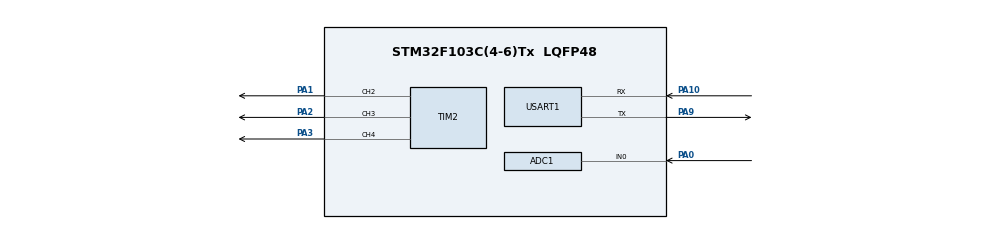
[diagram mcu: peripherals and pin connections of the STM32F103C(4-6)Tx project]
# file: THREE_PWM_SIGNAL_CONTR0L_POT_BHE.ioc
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ADC1.Channel-0\#ChannelRegularConversion=ADC_CHANNEL_0
ADC1.NbrOfConversionFlag=1
ADC1.Rank-0\#ChannelRegularConversion=1
ADC1.SamplingTime-0\#ChannelRegularConversion=ADC_SAMPLETIME_1CYCLE_5
ADC1.master=1
Mcu.Family=STM32F1
Mcu.Name=STM32F103C(4-6)Tx
Mcu.Package=LQFP48
NVIC.PriorityGroup=NVIC_PRIORITYGROUP_4
PA0-WKUP.Signal=ADCx_IN0
PA1.Signal=S_TIM2_CH2
PA10.Mode=Asynchronous
PA10.Signal=USART1_RX
PA2.Signal=S_TIM2_CH3
PA3.Signal=S_TIM2_CH4
PA9.Mode=Asynchronous
PA9.Signal=USART1_TX
PD0-OSC_IN.Mode=HSE-External-Oscillator
PD0-OSC_IN.Signal=RCC_OSC_IN
PD1-OSC_OUT.Mode=HSE-External-Oscillator
PD1-OSC_OUT.Signal=RCC_OSC_OUT
ProjectManager.HeapSize=0x200
ProjectManager.StackSize=0x400
ProjectManager.TargetToolchain=STM32CubeIDE
RCC.APB1Freq_Value=8000000
RCC.APB2Freq_Value=8000000
SH.ADCx_IN0.0=ADC1_IN0,IN0
SH.S_TIM2_CH2.0=TIM2_CH2,PWM Generation2 CH2
SH.S_TIM2_CH3.0=TIM2_CH3,PWM Generation3 CH3
SH.S_TIM2_CH4.0=TIM2_CH4,PWM Generation4 CH4
TIM2.Channel-PWM\ Generation2\ CH2=TIM_CHANNEL_2
TIM2.Channel-PWM\ Generation3\ CH3=TIM_CHANNEL_3
TIM2.Channel-PWM\ Generation4\ CH4=TIM_CHANNEL_4
USART1.VirtualMode=VM_ASYNC
VP_TIM2_VS_ClockSourceINT.Mode=Internal
board=custom

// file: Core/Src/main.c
/* USER CODE BEGIN Header */
/**
  ******************************************************************************
  * @file           : main.c
  * @brief          : Main program body
  ******************************************************************************
  * @attention
  *
  * Copyright (c) 2023 STMicroelectronics.
  * All rights reserved.
  *
  * This software is licensed under terms that can be found in the LICENSE file
  * in the root directory of this software component.
  * If no LICENSE file comes with this software, it is provided AS-IS.
  *
  ******************************************************************************
  */
/* USER CODE END Header */
#include "main.h"

ADC_HandleTypeDef hadc1;

TIM_HandleTypeDef htim2;

UART_HandleTypeDef huart1;

void SystemClock_Config(void);
static void MX_GPIO_Init(void);
static void MX_ADC1_Init(void);
static void MX_TIM2_Init(void);
static void MX_USART1_UART_Init(void);

int main(void)
{

	uint16_t test;
	char msg[10];

  /* MCU Configuration--------------------------------------------------------*/

  /* Reset of all peripherals, Initializes the Flash interface and the Systick. */
  HAL_Init();

  /* Configure the system clock */
  SystemClock_Config();

  /* Initialize all configured peripherals */
  MX_GPIO_Init();
  MX_ADC1_Init();
  MX_TIM2_Init();
  MX_USART1_UART_Init();
  /* USER CODE BEGIN 2 */

  /* Start PWM for 2 */
    if (HAL_TIM_PWM_Start(&htim2, TIM_CHANNEL_2) != HAL_OK)
    {
      /* PWM Generation Error */
      Error_Handler();
    }

    if (HAL_TIM_PWM_Start(&htim2, TIM_CHANNEL_3) != HAL_OK)
    {
      /* PWM Generation Error */
      Error_Handler();
    }

    if (HAL_TIM_PWM_Start(&htim2, TIM_CHANNEL_4) != HAL_OK)
    {
      /* PWM Generation Error */
      Error_Handler();
    }

  /* USER CODE END 2 */

  /* Infinite loop */
  while (1)
  {

	 HAL_ADC_Start(&hadc1);
	 HAL_ADC_PollForConversion(&hadc1,10000);
	 test=HAL_ADC_GetValue(&hadc1);

	 uint16_t potValue = HAL_ADC_GetValue(&hadc1);
	 uint32_t dutyCycle = (uint32_t)((float)potValue / 4095.0 * 35999.0); // Assuming 12-bit ADC

	 test = test*0.001220703125; // conversion adc value into voltage
	 sprintf(msg,"%hu\r\n",test);
     HAL_UART_Transmit(&huart1,(uint8_t *)msg,strlen(msg),100000);
     HAL_Delay(500);

     __HAL_TIM_SET_COMPARE(&htim2, TIM_CHANNEL_2, dutyCycle);

     __HAL_TIM_SET_COMPARE(&htim2, TIM_CHANNEL_3, dutyCycle);

     __HAL_TIM_SET_COMPARE(&htim2, TIM_CHANNEL_3, dutyCycle);

	 HAL_TIM_PWM_Start(&htim2, TIM_CHANNEL_2);

	 		      // Delay for a while
	 	HAL_Delay(500);

	 		      // Turn off the LED on PA1
	 	HAL_TIM_PWM_Stop(&htim2, TIM_CHANNEL_2);

	 		      // Turn on the LED on PA2 (Channel 2)
	 	HAL_TIM_PWM_Start(&htim2, TIM_CHANNEL_3);

	 		      // Delay for a while
	 	HAL_Delay(500);

	 		      // Turn off the LED on PA2
	 	HAL_TIM_PWM_Stop(&htim2, TIM_CHANNEL_3);

	 		      // Turn on the LED on PA3 (Channel 3)
	 	HAL_TIM_PWM_Start(&htim2, TIM_CHANNEL_4);

	 		      // Delay for a while
	 	HAL_Delay(500);

	 		      // Turn off the LED on PA3
	 	HAL_TIM_PWM_Stop(&htim2, TIM_CHANNEL_4);
  }
}

void SystemClock_Config(void)
{
  RCC_OscInitTypeDef RCC_OscInitStruct = {0};
  RCC_ClkInitTypeDef RCC_ClkInitStruct = {0};
  RCC_PeriphCLKInitTypeDef PeriphClkInit = {0};

  /** Initializes the RCC Oscillators according to the specified parameters
  * in the RCC_OscInitTypeDef structure.
  */
  RCC_OscInitStruct.OscillatorType = RCC_OSCILLATORTYPE_HSI;
  RCC_OscInitStruct.HSIState = RCC_HSI_ON;
  RCC_OscInitStruct.HSICalibrationValue = RCC_HSICALIBRATION_DEFAULT;
  RCC_OscInitStruct.PLL.PLLState = RCC_PLL_NONE;
  if (HAL_RCC_OscConfig(&RCC_OscInitStruct) != HAL_OK)
  {
    Error_Handler();
  }

  /** Initializes the CPU, AHB and APB buses clocks
  */
  RCC_ClkInitStruct.ClockType = RCC_CLOCKTYPE_HCLK|RCC_CLOCKTYPE_SYSCLK
                              |RCC_CLOCKTYPE_PCLK1|RCC_CLOCKTYPE_PCLK2;
  RCC_ClkInitStruct.SYSCLKSource = RCC_SYSCLKSOURCE_HSI;
  RCC_ClkInitStruct.AHBCLKDivider = RCC_SYSCLK_DIV1;
  RCC_ClkInitStruct.APB1CLKDivider = RCC_HCLK_DIV1;
  RCC_ClkInitStruct.APB2CLKDivider = RCC_HCLK_DIV1;

  if (HAL_RCC_ClockConfig(&RCC_ClkInitStruct, FLASH_LATENCY_0) != HAL_OK)
  {
    Error_Handler();
  }
  PeriphClkInit.PeriphClockSelection = RCC_PERIPHCLK_ADC;
  PeriphClkInit.AdcClockSelection = RCC_ADCPCLK2_DIV2;
  if (HAL_RCCEx_PeriphCLKConfig(&PeriphClkInit) != HAL_OK)
  {
    Error_Handler();
  }
}

static void MX_ADC1_Init(void)
{

  ADC_ChannelConfTypeDef sConfig = {0};

  /** Common config
  */
  hadc1.Instance = ADC1;
  hadc1.Init.ScanConvMode = ADC_SCAN_DISABLE;
  hadc1.Init.ContinuousConvMode = DISABLE;
  hadc1.Init.DiscontinuousConvMode = DISABLE;
  hadc1.Init.ExternalTrigConv = ADC_SOFTWARE_START;
  hadc1.Init.DataAlign = ADC_DATAALIGN_RIGHT;
  hadc1.Init.NbrOfConversion = 1;
  if (HAL_ADC_Init(&hadc1) != HAL_OK)
  {
    Error_Handler();
  }

  /** Configure Regular Channel
  */
  sConfig.Channel = ADC_CHANNEL_0;
  sConfig.Rank = ADC_REGULAR_RANK_1;
  sConfig.SamplingTime = ADC_SAMPLETIME_1CYCLE_5;
  if (HAL_ADC_ConfigChannel(&hadc1, &sConfig) != HAL_OK)
  {
    Error_Handler();
  }

}

static void MX_TIM2_Init(void)
{

  TIM_ClockConfigTypeDef sClockSourceConfig = {0};
  TIM_MasterConfigTypeDef sMasterConfig = {0};
  TIM_OC_InitTypeDef sConfigOC = {0};

  htim2.Instance = TIM2;
  htim2.Init.Prescaler = 0;
  htim2.Init.CounterMode = TIM_COUNTERMODE_UP;
  htim2.Init.Period = 35999;
  htim2.Init.ClockDivision = TIM_CLOCKDIVISION_DIV1;
  htim2.Init.AutoReloadPreload = TIM_AUTORELOAD_PRELOAD_DISABLE;
  if (HAL_TIM_Base_Init(&htim2) != HAL_OK)
  {
    Error_Handler();
  }
  //sClockSourceConfig.ClockSource = TIM_CLOCKSOURCE_INTERNAL;
  //if (HAL_TIM_ConfigClockSource(&htim2, &sClockSourceConfig) != HAL_OK)
  //{
   // Error_Handler();
  //}
  //if (HAL_TIM_PWM_Init(&htim2) != HAL_OK)
  //{
    //Error_Handler();
  //}
  //sMasterConfig.MasterOutputTrigger = TIM_TRGO_RESET;
  //sMasterConfig.MasterSlaveMode = TIM_MASTERSLAVEMODE_DISABLE;
  //if (HAL_TIMEx_MasterConfigSynchronization(&htim2, &sMasterConfig) != HAL_OK)
  //{
    //Error_Handler();
  //}
  sConfigOC.OCMode = TIM_OCMODE_PWM1;
  sConfigOC.Pulse = 17999;
  sConfigOC.OCPolarity = TIM_OCPOLARITY_HIGH;
  sConfigOC.OCFastMode = TIM_OCFAST_DISABLE;
  if (HAL_TIM_PWM_ConfigChannel(&htim2, &sConfigOC, TIM_CHANNEL_2) != HAL_OK)
  {
    Error_Handler();
  }

  // CONFIGURE CHANNEL 4 FOR PWM
  sConfigOC.OCMode = TIM_OCMODE_PWM1;
    sConfigOC.Pulse = 8999;
    sConfigOC.OCPolarity = TIM_OCPOLARITY_HIGH;
    sConfigOC.OCFastMode = TIM_OCFAST_DISABLE;
    if (HAL_TIM_PWM_ConfigChannel(&htim2, &sConfigOC, TIM_CHANNEL_3) != HAL_OK)
    {
      Error_Handler();
    }

  // CONFIGURE CHANNEL 3 FOR PWM
  sConfigOC.OCMode = TIM_OCMODE_PWM1;
  sConfigOC.Pulse = 26999; // Adjust pulse for the third LED (120-degree phase shift)
  sConfigOC.OCPolarity = TIM_OCPOLARITY_HIGH;
  sConfigOC.OCFastMode = TIM_OCFAST_DISABLE;
  if (HAL_TIM_PWM_ConfigChannel(&htim2, &sConfigOC, TIM_CHANNEL_4) != HAL_OK)
  {
    Error_Handler();
  }

  HAL_TIM_MspPostInit(&htim2);
  __HAL_TIM_MOE_ENABLE(&htim2);

}

static void MX_USART1_UART_Init(void)
{

  huart1.Instance = USART1;
  huart1.Init.BaudRate = 9600;
  huart1.Init.WordLength = UART_WORDLENGTH_8B;
  huart1.Init.StopBits = UART_STOPBITS_1;
  huart1.Init.Parity = UART_PARITY_NONE;
  huart1.Init.Mode = UART_MODE_TX_RX;
  huart1.Init.HwFlowCtl = UART_HWCONTROL_NONE;
  huart1.Init.OverSampling = UART_OVERSAMPLING_16;
  if (HAL_UART_Init(&huart1) != HAL_OK)
  {
    Error_Handler();
  }

}

static void MX_GPIO_Init(void)
{

   GPIO_InitTypeDef GPIO_InitStruct = {0};

  /* GPIO Ports Clock Enable */
  __HAL_RCC_GPIOD_CLK_ENABLE();
  __HAL_RCC_GPIOA_CLK_ENABLE();

  /* Configure GPIO pin : PA1 (for Channel 1) */
    GPIO_InitStruct.Pin = GPIO_PIN_1;
    GPIO_InitStruct.Mode = GPIO_MODE_AF_PP;
    GPIO_InitStruct.Speed = GPIO_SPEED_FREQ_LOW;
    HAL_GPIO_Init(GPIOA, &GPIO_InitStruct);

    /* Configure GPIO pin : PA2 (for Channel 2) */
    GPIO_InitStruct.Pin = GPIO_PIN_2;
    GPIO_InitStruct.Mode = GPIO_MODE_AF_PP;
    GPIO_InitStruct.Speed = GPIO_SPEED_FREQ_LOW;
    HAL_GPIO_Init(GPIOA, &GPIO_InitStruct);

    /* Configure GPIO pin : PA2 (for Channel 3) */
    GPIO_InitStruct.Pin = GPIO_PIN_3;
    GPIO_InitStruct.Mode = GPIO_MODE_AF_PP;
    GPIO_InitStruct.Speed = GPIO_SPEED_FREQ_LOW;
    HAL_GPIO_Init(GPIOA, &GPIO_InitStruct);
}

void Error_Handler(void)
{
  __disable_irq();
  while (1)
  {
  }
}
